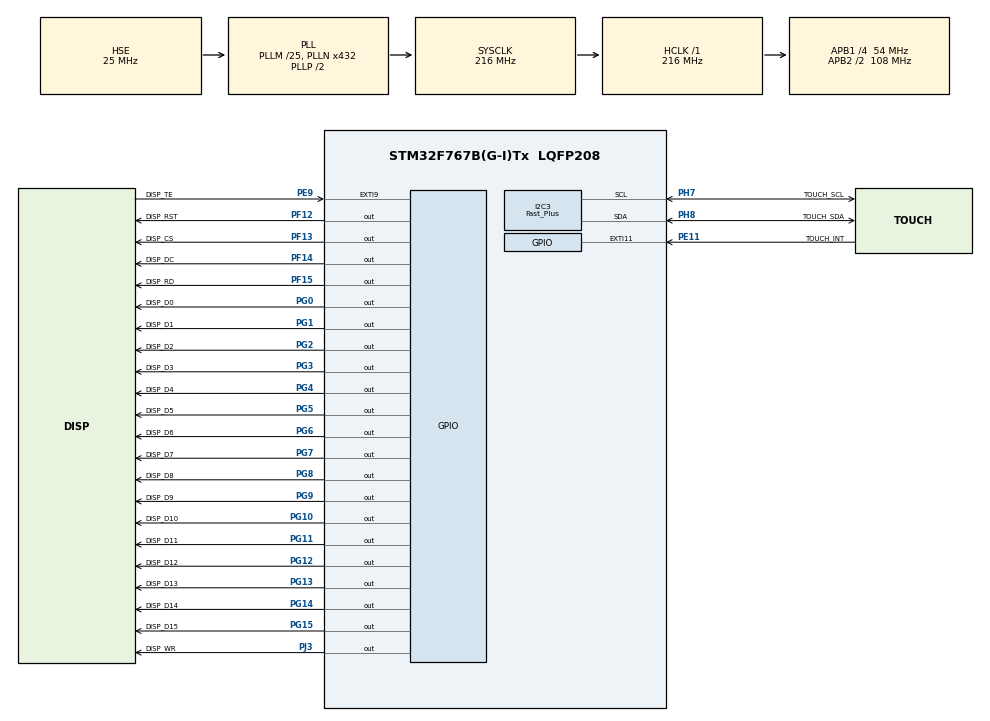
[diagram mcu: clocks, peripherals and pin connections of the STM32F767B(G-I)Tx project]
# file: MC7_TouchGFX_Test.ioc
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CORTEX_M7.ART_ACCLERATOR_ENABLE=0
CORTEX_M7.CPU_DCache=Enabled
CORTEX_M7.CPU_ICache=Enabled
CORTEX_M7.FlashInterface=AXI_Enabled
CORTEX_M7.PREFETCH_ENABLE=1
I2C3.DualAddressMode=I2C_DUALADDRESS_DISABLE
I2C3.I2C_Speed_Mode=I2C_Fast_Plus
I2C3.Timing=0x00200922
Mcu.Family=STM32F7
Mcu.Name=STM32F767B(G-I)Tx
Mcu.Package=LQFP208
NVIC.EXTI15_10_IRQn=true\:1\:0\:true\:false\:true\:true\:true
NVIC.EXTI9_5_IRQn=true\:4\:0\:true\:false\:true\:true\:true
NVIC.PriorityGroup=NVIC_PRIORITYGROUP_4
NVIC.TIM5_IRQn=true\:5\:0\:true\:false\:true\:true\:true
PE11.GPIO_Label=TOUCH_INT
PE11.GPIO_ModeDefaultEXTI=GPIO_MODE_IT_FALLING
PE11.Signal=GPXTI11
PE9.GPIO_Label=DISP_TE
PE9.GPIO_ModeDefaultEXTI=GPIO_MODE_IT_RISING
PE9.Signal=GPXTI9
PF12.GPIO_Label=DISP_RST
PF12.GPIO_Speed=GPIO_SPEED_FREQ_VERY_HIGH
PF12.Signal=GPIO_Output
PF13.GPIO_Label=DISP_CS
PF13.GPIO_Speed=GPIO_SPEED_FREQ_VERY_HIGH
PF13.Signal=GPIO_Output
PF14.GPIO_Label=DISP_DC
PF14.GPIO_Speed=GPIO_SPEED_FREQ_VERY_HIGH
PF14.Signal=GPIO_Output
PF15.GPIO_Label=DISP_RD
PF15.GPIO_Speed=GPIO_SPEED_FREQ_VERY_HIGH
PF15.Signal=GPIO_Output
PG0.GPIO_Label=DISP_D0
PG0.GPIO_Speed=GPIO_SPEED_FREQ_VERY_HIGH
PG0.Signal=GPIO_Output
PG1.GPIO_Label=DISP_D1
PG1.GPIO_Speed=GPIO_SPEED_FREQ_VERY_HIGH
PG1.Signal=GPIO_Output
PG10.GPIO_Label=DISP_D10
PG10.GPIO_Speed=GPIO_SPEED_FREQ_VERY_HIGH
PG10.Signal=GPIO_Output
PG11.GPIO_Label=DISP_D11
PG11.GPIO_Speed=GPIO_SPEED_FREQ_VERY_HIGH
PG11.Signal=GPIO_Output
PG12.GPIO_Label=DISP_D12
PG12.GPIO_Speed=GPIO_SPEED_FREQ_VERY_HIGH
PG12.Signal=GPIO_Output
PG13.GPIO_Label=DISP_D13
PG13.GPIO_Speed=GPIO_SPEED_FREQ_VERY_HIGH
PG13.Signal=GPIO_Output
PG14.GPIO_Label=DISP_D14
PG14.GPIO_Speed=GPIO_SPEED_FREQ_VERY_HIGH
PG14.Signal=GPIO_Output
PG15.GPIO_Label=DISP_D15
PG15.GPIO_Speed=GPIO_SPEED_FREQ_VERY_HIGH
PG15.Signal=GPIO_Output
PG2.GPIO_Label=DISP_D2
PG2.GPIO_Speed=GPIO_SPEED_FREQ_VERY_HIGH
PG2.Signal=GPIO_Output
PG3.GPIO_Label=DISP_D3
PG3.GPIO_Speed=GPIO_SPEED_FREQ_VERY_HIGH
PG3.Signal=GPIO_Output
PG4.GPIO_Label=DISP_D4
PG4.GPIO_Speed=GPIO_SPEED_FREQ_VERY_HIGH
PG4.Signal=GPIO_Output
PG5.GPIO_Label=DISP_D5
PG5.GPIO_Speed=GPIO_SPEED_FREQ_VERY_HIGH
PG5.Signal=GPIO_Output
PG6.GPIO_Label=DISP_D6
PG6.GPIO_Speed=GPIO_SPEED_FREQ_VERY_HIGH
PG6.Signal=GPIO_Output
PG7.GPIO_Label=DISP_D7
PG7.GPIO_Speed=GPIO_SPEED_FREQ_VERY_HIGH
PG7.Signal=GPIO_Output
PG8.GPIO_Label=DISP_D8
PG8.GPIO_Speed=GPIO_SPEED_FREQ_VERY_HIGH
PG8.Signal=GPIO_Output
PG9.GPIO_Label=DISP_D9
PG9.GPIO_Speed=GPIO_SPEED_FREQ_VERY_HIGH
PG9.Signal=GPIO_Output
PH0/OSC_IN.Mode=HSE-External-Oscillator
PH0/OSC_IN.Signal=RCC_OSC_IN
PH1/OSC_OUT.Mode=HSE-External-Oscillator
PH1/OSC_OUT.Signal=RCC_OSC_OUT
PH7.GPIO_Label=TOUCH_SCL
PH7.Mode=I2C
PH7.Signal=I2C3_SCL
PH8.GPIO_Label=TOUCH_SDA
PH8.Mode=I2C
PH8.Signal=I2C3_SDA
PJ3.GPIO_Label=DISP_WR
PJ3.GPIO_Speed=GPIO_SPEED_FREQ_VERY_HIGH
PJ3.Signal=GPIO_Output
ProjectManager.HeapSize=0x200
ProjectManager.StackSize=0x400
ProjectManager.TargetToolchain=STM32CubeIDE
RCC.AHBFreq_Value=216000000
RCC.APB1CLKDivider=RCC_HCLK_DIV4
RCC.APB1Freq_Value=54000000
RCC.APB1TimFreq_Value=108000000
RCC.APB2CLKDivider=RCC_HCLK_DIV2
RCC.APB2Freq_Value=108000000
RCC.APB2TimFreq_Value=216000000
RCC.CortexFreq_Value=216000000
RCC.HCLKFreq_Value=216000000
RCC.HSE_Timout=100
RCC.HSE_VALUE=25000000
RCC.HSI_VALUE=16000000
RCC.LSE_VALUE=32768
RCC.PLLM=25
RCC.PLLN=432
RCC.PLLSourceVirtual=RCC_PLLSOURCE_HSE
RCC.SYSCLKFreq_VALUE=216000000
RCC.SYSCLKSource=RCC_SYSCLKSOURCE_PLLCLK
RCC.USBFreq_Value=216000000
RCC.VCOOutputFreq_Value=432000000
STMicroelectronics.X-CUBE-TOUCHGFX.4.13.0.ApplicationCcGraphicsJjApplication=TouchGFXOoGenerator
STMicroelectronics.X-CUBE-TOUCHGFX.4.13.0.tgfx_block_size=384000
STMicroelectronics.X-CUBE-TOUCHGFX.4.13.0.tgfx_buffering_strategy=Partial
STMicroelectronics.X-CUBE-TOUCHGFX.4.13.0.tgfx_custom_height=480
STMicroelectronics.X-CUBE-TOUCHGFX.4.13.0.tgfx_custom_width=800
STMicroelectronics.X-CUBE-TOUCHGFX.4.13.0.tgfx_hardware_accelerator=dma_none
STMicroelectronics.X-CUBE-TOUCHGFX.4.13.0.tgfx_number_of_blocks=2
STMicroelectronics.X-CUBE-TOUCHGFX.4.13.0.tgfx_pixel_format=RGB565\:16
TIM5.AutoReloadPreload=TIM_AUTORELOAD_PRELOAD_ENABLE
TIM5.ClockDivision=TIM_CLOCKDIVISION_DIV2
TIM5.CounterMode=TIM_COUNTERMODE_UP
TIM5.Period=16667
TIM5.Prescaler=54
VP_CRC_VS_CRC.Mode=CRC_Activate
VP_STMicroelectronics.X-CUBE-TOUCHGFX_VS_GraphicsJjApplication_4.13.0.Mode=GraphicsJjApplication
VP_TIM5_VS_ClockSourceINT.Mode=Internal
board=custom

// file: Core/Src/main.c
/* USER CODE BEGIN Header */
/**
  ******************************************************************************
  * @file           : main.c
  * @brief          : Main program body
  ******************************************************************************
  * @attention
  *
  * <h2><center>&copy; Copyright (c) 2020 STMicroelectronics.
  * All rights reserved.</center></h2>
  *
  * This software component is licensed by ST under BSD 3-Clause license,
  * the "License"; You may not use this file except in compliance with the
  * License. You may obtain a copy of the License at:
  *                        opensource.org/licenses/BSD-3-Clause
  *
  ******************************************************************************
  */
/* USER CODE END Header */

#include "main.h"
#include "app_touchgfx.h"

/* USER CODE BEGIN Includes */
/*#include "SSD1963.h"
#include "FT5XX6.h"*/
/* USER CODE END Includes */

CRC_HandleTypeDef hcrc;

I2C_HandleTypeDef hi2c3;

TIM_HandleTypeDef htim5;

/* USER CODE BEGIN PV */
void touchgfx_signalVSyncTimer(void);
/* USER CODE END PV */

void SystemClock_Config(void);
static void MX_GPIO_Init(void);
static void MX_I2C3_Init(void);
static void MX_CRC_Init(void);
static void MX_TIM5_Init(void);

int main(void)
{

  /* Enable I-Cache---------------------------------------------------------*/
  SCB_EnableICache();

  /* Enable D-Cache---------------------------------------------------------*/
  SCB_EnableDCache();

  /* MCU Configuration--------------------------------------------------------*/

  /* Reset of all peripherals, Initializes the Flash interface and the Systick. */
  HAL_Init();

  /* Configure the system clock */
  SystemClock_Config();

  /* USER CODE BEGIN SysInit */
  SystemCoreClockUpdate();
  /* USER CODE END SysInit */

  /* Initialize all configured peripherals */
  MX_GPIO_Init();
  MX_I2C3_Init();
  MX_CRC_Init();
  MX_TIM5_Init();
  MX_TouchGFX_Init();

  /* Infinite loop */
  while (1)
  {

  MX_TouchGFX_Process();
  }
}

void SystemClock_Config(void)
{
  RCC_OscInitTypeDef RCC_OscInitStruct = {0};
  RCC_ClkInitTypeDef RCC_ClkInitStruct = {0};
  RCC_PeriphCLKInitTypeDef PeriphClkInitStruct = {0};

  /** Configure the main internal regulator output voltage
  */
  __HAL_RCC_PWR_CLK_ENABLE();
  __HAL_PWR_VOLTAGESCALING_CONFIG(PWR_REGULATOR_VOLTAGE_SCALE1);
  /** Initializes the CPU, AHB and APB busses clocks
  */
  RCC_OscInitStruct.OscillatorType = RCC_OSCILLATORTYPE_HSE;
  RCC_OscInitStruct.HSEState = RCC_HSE_ON;
  RCC_OscInitStruct.PLL.PLLState = RCC_PLL_ON;
  RCC_OscInitStruct.PLL.PLLSource = RCC_PLLSOURCE_HSE;
  RCC_OscInitStruct.PLL.PLLM = 25;
  RCC_OscInitStruct.PLL.PLLN = 432;
  RCC_OscInitStruct.PLL.PLLP = RCC_PLLP_DIV2;
  RCC_OscInitStruct.PLL.PLLQ = 2;
  if (HAL_RCC_OscConfig(&RCC_OscInitStruct) != HAL_OK)
  {
    Error_Handler();
  }
  /** Activate the Over-Drive mode
  */
  if (HAL_PWREx_EnableOverDrive() != HAL_OK)
  {
    Error_Handler();
  }
  /** Initializes the CPU, AHB and APB busses clocks
  */
  RCC_ClkInitStruct.ClockType = RCC_CLOCKTYPE_HCLK|RCC_CLOCKTYPE_SYSCLK
                              |RCC_CLOCKTYPE_PCLK1|RCC_CLOCKTYPE_PCLK2;
  RCC_ClkInitStruct.SYSCLKSource = RCC_SYSCLKSOURCE_PLLCLK;
  RCC_ClkInitStruct.AHBCLKDivider = RCC_SYSCLK_DIV1;
  RCC_ClkInitStruct.APB1CLKDivider = RCC_HCLK_DIV4;
  RCC_ClkInitStruct.APB2CLKDivider = RCC_HCLK_DIV2;

  if (HAL_RCC_ClockConfig(&RCC_ClkInitStruct, FLASH_LATENCY_7) != HAL_OK)
  {
    Error_Handler();
  }
  PeriphClkInitStruct.PeriphClockSelection = RCC_PERIPHCLK_I2C3;
  PeriphClkInitStruct.I2c3ClockSelection = RCC_I2C3CLKSOURCE_PCLK1;
  if (HAL_RCCEx_PeriphCLKConfig(&PeriphClkInitStruct) != HAL_OK)
  {
    Error_Handler();
  }
}

static void MX_CRC_Init(void)
{

  hcrc.Instance = CRC;
  hcrc.Init.DefaultPolynomialUse = DEFAULT_POLYNOMIAL_ENABLE;
  hcrc.Init.DefaultInitValueUse = DEFAULT_INIT_VALUE_ENABLE;
  hcrc.Init.InputDataInversionMode = CRC_INPUTDATA_INVERSION_NONE;
  hcrc.Init.OutputDataInversionMode = CRC_OUTPUTDATA_INVERSION_DISABLE;
  hcrc.InputDataFormat = CRC_INPUTDATA_FORMAT_BYTES;
  if (HAL_CRC_Init(&hcrc) != HAL_OK)
  {
    Error_Handler();
  }

}

static void MX_I2C3_Init(void)
{

  hi2c3.Instance = I2C3;
  hi2c3.Init.Timing = 0x00200922;
  hi2c3.Init.OwnAddress1 = 0;
  hi2c3.Init.AddressingMode = I2C_ADDRESSINGMODE_7BIT;
  hi2c3.Init.DualAddressMode = I2C_DUALADDRESS_DISABLE;
  hi2c3.Init.OwnAddress2 = 0;
  hi2c3.Init.OwnAddress2Masks = I2C_OA2_NOMASK;
  hi2c3.Init.GeneralCallMode = I2C_GENERALCALL_DISABLE;
  hi2c3.Init.NoStretchMode = I2C_NOSTRETCH_DISABLE;
  if (HAL_I2C_Init(&hi2c3) != HAL_OK)
  {
    Error_Handler();
  }
  /** Configure Analogue filter
  */
  if (HAL_I2CEx_ConfigAnalogFilter(&hi2c3, I2C_ANALOGFILTER_ENABLE) != HAL_OK)
  {
    Error_Handler();
  }
  /** Configure Digital filter
  */
  if (HAL_I2CEx_ConfigDigitalFilter(&hi2c3, 0) != HAL_OK)
  {
    Error_Handler();
  }
  /** I2C Enable Fast Mode Plus
  */
  HAL_I2CEx_EnableFastModePlus(I2C_FASTMODEPLUS_I2C3);

}

static void MX_TIM5_Init(void)
{

  TIM_ClockConfigTypeDef sClockSourceConfig = {0};
  TIM_MasterConfigTypeDef sMasterConfig = {0};

  htim5.Instance = TIM5;
  htim5.Init.Prescaler = 54;
  htim5.Init.CounterMode = TIM_COUNTERMODE_UP;
  htim5.Init.Period = 16667;
  htim5.Init.ClockDivision = TIM_CLOCKDIVISION_DIV2;
  htim5.Init.AutoReloadPreload = TIM_AUTORELOAD_PRELOAD_ENABLE;
  if (HAL_TIM_Base_Init(&htim5) != HAL_OK)
  {
    Error_Handler();
  }
  sClockSourceConfig.ClockSource = TIM_CLOCKSOURCE_INTERNAL;
  if (HAL_TIM_ConfigClockSource(&htim5, &sClockSourceConfig) != HAL_OK)
  {
    Error_Handler();
  }
  sMasterConfig.MasterOutputTrigger = TIM_TRGO_RESET;
  sMasterConfig.MasterSlaveMode = TIM_MASTERSLAVEMODE_DISABLE;
  if (HAL_TIMEx_MasterConfigSynchronization(&htim5, &sMasterConfig) != HAL_OK)
  {
    Error_Handler();
  }

}

static void MX_GPIO_Init(void)
{
  GPIO_InitTypeDef GPIO_InitStruct = {0};

  /* GPIO Ports Clock Enable */
  __HAL_RCC_GPIOH_CLK_ENABLE();
  __HAL_RCC_GPIOJ_CLK_ENABLE();
  __HAL_RCC_GPIOF_CLK_ENABLE();
  __HAL_RCC_GPIOG_CLK_ENABLE();
  __HAL_RCC_GPIOE_CLK_ENABLE();

  /*Configure GPIO pin Output Level */
  HAL_GPIO_WritePin(DISP_WR_GPIO_Port, DISP_WR_Pin, GPIO_PIN_RESET);

  /*Configure GPIO pin Output Level */
  HAL_GPIO_WritePin(GPIOF, DISP_RST_Pin|DISP_CS_Pin|DISP_DC_Pin|DISP_RD_Pin, GPIO_PIN_RESET);

  /*Configure GPIO pin Output Level */
  HAL_GPIO_WritePin(GPIOG, DISP_D0_Pin|DISP_D1_Pin|DISP_D2_Pin|DISP_D3_Pin
                          |DISP_D4_Pin|DISP_D5_Pin|DISP_D6_Pin|DISP_D7_Pin
                          |DISP_D8_Pin|DISP_D9_Pin|DISP_D10_Pin|DISP_D11_Pin
                          |DISP_D12_Pin|DISP_D13_Pin|DISP_D14_Pin|DISP_D15_Pin, GPIO_PIN_RESET);

  /*Configure GPIO pin : DISP_WR_Pin */
  GPIO_InitStruct.Pin = DISP_WR_Pin;
  GPIO_InitStruct.Mode = GPIO_MODE_OUTPUT_PP;
  GPIO_InitStruct.Pull = GPIO_NOPULL;
  GPIO_InitStruct.Speed = GPIO_SPEED_FREQ_VERY_HIGH;
  HAL_GPIO_Init(DISP_WR_GPIO_Port, &GPIO_InitStruct);

  /*Configure GPIO pins : DISP_RST_Pin DISP_CS_Pin DISP_DC_Pin DISP_RD_Pin */
  GPIO_InitStruct.Pin = DISP_RST_Pin|DISP_CS_Pin|DISP_DC_Pin|DISP_RD_Pin;
  GPIO_InitStruct.Mode = GPIO_MODE_OUTPUT_PP;
  GPIO_InitStruct.Pull = GPIO_NOPULL;
  GPIO_InitStruct.Speed = GPIO_SPEED_FREQ_VERY_HIGH;
  HAL_GPIO_Init(GPIOF, &GPIO_InitStruct);

  /*Configure GPIO pins : DISP_D0_Pin DISP_D1_Pin DISP_D2_Pin DISP_D3_Pin
                           DISP_D4_Pin DISP_D5_Pin DISP_D6_Pin DISP_D7_Pin
                           DISP_D8_Pin DISP_D9_Pin DISP_D10_Pin DISP_D11_Pin
                           DISP_D12_Pin DISP_D13_Pin DISP_D14_Pin DISP_D15_Pin */
  GPIO_InitStruct.Pin = DISP_D0_Pin|DISP_D1_Pin|DISP_D2_Pin|DISP_D3_Pin
                          |DISP_D4_Pin|DISP_D5_Pin|DISP_D6_Pin|DISP_D7_Pin
                          |DISP_D8_Pin|DISP_D9_Pin|DISP_D10_Pin|DISP_D11_Pin
                          |DISP_D12_Pin|DISP_D13_Pin|DISP_D14_Pin|DISP_D15_Pin;
  GPIO_InitStruct.Mode = GPIO_MODE_OUTPUT_PP;
  GPIO_InitStruct.Pull = GPIO_NOPULL;
  GPIO_InitStruct.Speed = GPIO_SPEED_FREQ_VERY_HIGH;
  HAL_GPIO_Init(GPIOG, &GPIO_InitStruct);

  /*Configure GPIO pin : DISP_TE_Pin */
  GPIO_InitStruct.Pin = DISP_TE_Pin;
  GPIO_InitStruct.Mode = GPIO_MODE_IT_RISING;
  GPIO_InitStruct.Pull = GPIO_NOPULL;
  HAL_GPIO_Init(DISP_TE_GPIO_Port, &GPIO_InitStruct);

  /*Configure GPIO pin : TOUCH_INT_Pin */
  GPIO_InitStruct.Pin = TOUCH_INT_Pin;
  GPIO_InitStruct.Mode = GPIO_MODE_IT_FALLING;
  GPIO_InitStruct.Pull = GPIO_NOPULL;
  HAL_GPIO_Init(TOUCH_INT_GPIO_Port, &GPIO_InitStruct);

  /* EXTI interrupt init*/
  HAL_NVIC_SetPriority(EXTI9_5_IRQn, 4, 0);
  HAL_NVIC_EnableIRQ(EXTI9_5_IRQn);

  HAL_NVIC_SetPriority(EXTI15_10_IRQn, 1, 0);
  HAL_NVIC_EnableIRQ(EXTI15_10_IRQn);

}

void Error_Handler(void)
{
}

/************************ (C) COPYRIGHT STMicroelectronics *****END OF FILE****/
